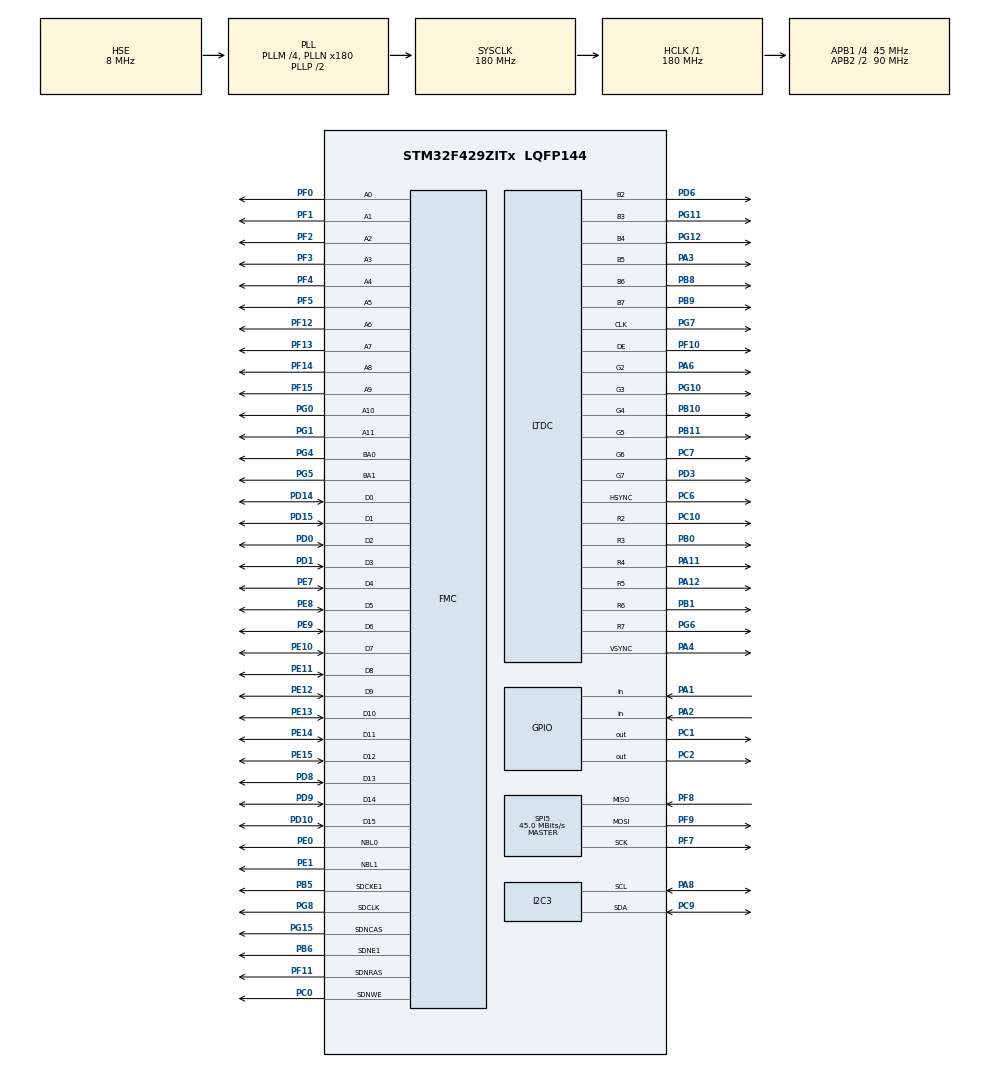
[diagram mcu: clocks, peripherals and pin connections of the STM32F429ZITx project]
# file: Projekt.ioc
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DMA2D.ColorMode=DMA2D_OUTPUT_RGB565
LTDC.ActiveH=320
LTDC.ActiveW=240
Mcu.Family=STM32F4
Mcu.Name=STM32F429ZITx
Mcu.Package=LQFP144
NVIC.PriorityGroup=NVIC_PRIORITYGROUP_4
NVIC.TIM6_DAC_IRQn=true\:0\:0\:false\:false\:true\:true\:true
PA1.Signal=GPIO_Input
PA11.Mode=RGB666
PA11.Signal=LTDC_R4
PA12.Mode=RGB666
PA12.Signal=LTDC_R5
PA2.Signal=GPIO_Input
PA3.Mode=RGB666
PA3.Signal=LTDC_B5
PA4.Mode=RGB666
PA4.Signal=LTDC_VSYNC
PA6.Mode=RGB666
PA6.Signal=LTDC_G2
PA8.Mode=I2C
PA8.Signal=I2C3_SCL
PB0.Mode=RGB666
PB0.Signal=LTDC_R3
PB1.Mode=RGB666
PB1.Signal=LTDC_R6
PB10.Mode=RGB666
PB10.Signal=LTDC_G4
PB11.Mode=RGB666
PB11.Signal=LTDC_G5
PB5.Mode=SdramChipSelect2_1
PB5.Signal=FMC_SDCKE1
PB6.Mode=SdramChipSelect2_1
PB6.Signal=FMC_SDNE1
PB8.Mode=RGB666
PB8.Signal=LTDC_B6
PB9.Mode=RGB666
PB9.Signal=LTDC_B7
PC0.Signal=FMC_SDNWE
PC1.Signal=GPIO_Output
PC10.Mode=RGB666
PC10.Signal=LTDC_R2
PC2.Signal=GPIO_Output
PC6.Mode=RGB666
PC6.Signal=LTDC_HSYNC
PC7.Mode=RGB666
PC7.Signal=LTDC_G6
PC9.Mode=I2C
PC9.Signal=I2C3_SDA
PD0.Signal=FMC_D2_DA2
PD1.Signal=FMC_D3_DA3
PD10.Signal=FMC_D15_DA15
PD14.Signal=FMC_D0_DA0
PD15.Signal=FMC_D1_DA1
PD3.Mode=RGB666
PD3.Signal=LTDC_G7
PD6.Mode=RGB666
PD6.Signal=LTDC_B2
PD8.Signal=FMC_D13_DA13
PD9.Signal=FMC_D14_DA14
PE0.Signal=FMC_NBL0
PE1.Signal=FMC_NBL1
PE10.Signal=FMC_D7_DA7
PE11.Signal=FMC_D8_DA8
PE12.Signal=FMC_D9_DA9
PE13.Signal=FMC_D10_DA10
PE14.Signal=FMC_D11_DA11
PE15.Signal=FMC_D12_DA12
PE7.Signal=FMC_D4_DA4
PE8.Signal=FMC_D5_DA5
PE9.Signal=FMC_D6_DA6
PF0.Signal=FMC_A0
PF1.Signal=FMC_A1
PF10.Mode=RGB666
PF10.Signal=LTDC_DE
PF11.Signal=FMC_SDNRAS
PF12.Signal=FMC_A6
PF13.Signal=FMC_A7
PF14.Signal=FMC_A8
PF15.Signal=FMC_A9
PF2.Signal=FMC_A2
PF3.Signal=FMC_A3
PF4.Signal=FMC_A4
PF5.Signal=FMC_A5
PF7.Mode=Full_Duplex_Master
PF7.Signal=SPI5_SCK
PF8.Mode=Full_Duplex_Master
PF8.Signal=SPI5_MISO
PF9.Mode=Full_Duplex_Master
PF9.Signal=SPI5_MOSI
PG0.Signal=FMC_A10
PG1.Signal=FMC_A11
PG10.Mode=RGB666
PG10.Signal=LTDC_G3
PG11.Mode=RGB666
PG11.Signal=LTDC_B3
PG12.Mode=RGB666
PG12.Signal=LTDC_B4
PG15.Signal=FMC_SDNCAS
PG4.Signal=FMC_A14_BA0
PG5.Signal=FMC_A15_BA1
PG6.Mode=RGB666
PG6.Signal=LTDC_R7
PG7.Mode=RGB666
PG7.Signal=LTDC_CLK
PG8.Signal=FMC_SDCLK
PH0/OSC_IN.Mode=HSE-External-Oscillator
PH0/OSC_IN.Signal=RCC_OSC_IN
PH1/OSC_OUT.Mode=HSE-External-Oscillator
PH1/OSC_OUT.Signal=RCC_OSC_OUT
ProjectManager.HeapSize=0x200
ProjectManager.StackSize=0x400
ProjectManager.TargetToolchain=STM32CubeIDE
RCC.48MHZClocksFreq_Value=90000000
RCC.AHBFreq_Value=180000000
RCC.APB1CLKDivider=RCC_HCLK_DIV4
RCC.APB1Freq_Value=45000000
RCC.APB1TimFreq_Value=90000000
RCC.APB2CLKDivider=RCC_HCLK_DIV2
RCC.APB2Freq_Value=90000000
RCC.APB2TimFreq_Value=180000000
RCC.CortexFreq_Value=180000000
RCC.HCLKFreq_Value=180000000
RCC.HSE_VALUE=8000000
RCC.HSI_VALUE=16000000
RCC.LSE_VALUE=32768
RCC.PLLM=4
RCC.PLLN=180
RCC.PLLSAIN=166
RCC.PLLSourceVirtual=RCC_PLLSOURCE_HSE
RCC.SYSCLKFreq_VALUE=180000000
RCC.SYSCLKSource=RCC_SYSCLKSOURCE_PLLCLK
RCC.VCOOutputFreq_Value=360000000
SH.FMC_A0.0=FMC_A0,12b-sda1
SH.FMC_A1.0=FMC_A1,12b-sda1
SH.FMC_A10.0=FMC_A10,12b-sda1
SH.FMC_A11.0=FMC_A11,12b-sda1
SH.FMC_A14_BA0.0=FMC_BA0,FourSdramBanks1
SH.FMC_A15_BA1.0=FMC_BA1,FourSdramBanks1
SH.FMC_A2.0=FMC_A2,12b-sda1
SH.FMC_A3.0=FMC_A3,12b-sda1
SH.FMC_A4.0=FMC_A4,12b-sda1
SH.FMC_A5.0=FMC_A5,12b-sda1
SH.FMC_A6.0=FMC_A6,12b-sda1
SH.FMC_A7.0=FMC_A7,12b-sda1
SH.FMC_A8.0=FMC_A8,12b-sda1
SH.FMC_A9.0=FMC_A9,12b-sda1
SH.FMC_D0_DA0.0=FMC_D0,sd-16b-d1
SH.FMC_D10_DA10.0=FMC_D10,sd-16b-d1
SH.FMC_D11_DA11.0=FMC_D11,sd-16b-d1
SH.FMC_D12_DA12.0=FMC_D12,sd-16b-d1
SH.FMC_D13_DA13.0=FMC_D13,sd-16b-d1
SH.FMC_D14_DA14.0=FMC_D14,sd-16b-d1
SH.FMC_D15_DA15.0=FMC_D15,sd-16b-d1
SH.FMC_D1_DA1.0=FMC_D1,sd-16b-d1
SH.FMC_D2_DA2.0=FMC_D2,sd-16b-d1
SH.FMC_D3_DA3.0=FMC_D3,sd-16b-d1
SH.FMC_D4_DA4.0=FMC_D4,sd-16b-d1
SH.FMC_D5_DA5.0=FMC_D5,sd-16b-d1
SH.FMC_D6_DA6.0=FMC_D6,sd-16b-d1
SH.FMC_D7_DA7.0=FMC_D7,sd-16b-d1
SH.FMC_D8_DA8.0=FMC_D8,sd-16b-d1
SH.FMC_D9_DA9.0=FMC_D9,sd-16b-d1
SH.FMC_NBL0.0=FMC_NBL0,Sd2ByteEnable1
SH.FMC_NBL1.0=FMC_NBL1,Sd2ByteEnable1
SH.FMC_SDCLK.0=FMC_SDCLK,12b-sda1
SH.FMC_SDNCAS.0=FMC_SDNCAS,12b-sda1
SH.FMC_SDNRAS.0=FMC_SDNRAS,12b-sda1
SH.FMC_SDNWE.0=FMC_SDNWE,12b-sda1
SPI5.CalculateBaudRate=45.0 MBits/s
SPI5.Direction=SPI_DIRECTION_2LINES
SPI5.Mode=SPI_MODE_MASTER
SPI5.VirtualType=VM_MASTER
TIM6.Period=9488
TIM6.Prescaler=9488
VP_DMA2D_VS_DMA2D.Mode=DMA2D_Activate
VP_TIM6_VS_ClockSourceINT.Mode=Enable_Timer
board=custom

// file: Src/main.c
/* USER CODE BEGIN Header */
/**
  ******************************************************************************
  * @file           : main.c
  * @brief          : Main program body
  ******************************************************************************
  * @attention
  *
  * <h2><center>&copy; Copyright (c) 2002 STMicroelectronics.
  * All rights reserved.</center></h2>
  *
  * This software component is licensed by ST under BSD 3-Clause license,
  * the "License"; You may not use this file except in compliance with the
  * License. You may obtain a copy of the License at:
  *                        opensource.org/licenses/BSD-3-Clause
  *
  ******************************************************************************
  */
/* USER CODE END Header */

#include "main.h"

/* USER CODE BEGIN Includes */
#include "stm32f429i_discovery_lcd.h"
#include "stm32f429xx.h"
#include "stdio.h"
#include <time.h>
/* USER CODE END Includes */

DMA2D_HandleTypeDef hdma2d;

I2C_HandleTypeDef hi2c3;

LTDC_HandleTypeDef hltdc;

SPI_HandleTypeDef hspi5;

TIM_HandleTypeDef htim6;

SDRAM_HandleTypeDef hsdram1;

/* USER CODE BEGIN PV */
int h = 0;
int min = 0;
int sec = 0;
/* USER CODE END PV */

void SystemClock_Config(void);
static void MX_GPIO_Init(void);
static void MX_DMA2D_Init(void);
static void MX_FMC_Init(void);
static void MX_I2C3_Init(void);
static void MX_LTDC_Init(void);
static void MX_SPI5_Init(void);
static void MX_TIM6_Init(void);

int main(void)
{

  /* MCU Configuration--------------------------------------------------------*/

  /* Reset of all peripherals, Initializes the Flash interface and the Systick. */
  HAL_Init();

  /* Configure the system clock */
  SystemClock_Config();

  /* Initialize all configured peripherals */
  MX_GPIO_Init();
  MX_DMA2D_Init();
  MX_FMC_Init();
  MX_I2C3_Init();
  MX_LTDC_Init();
  MX_SPI5_Init();
  MX_TIM6_Init();

  /* Infinite loop */
  /* USER CODE BEGIN WHILE */
   BSP_LCD_Init();
   BSP_LCD_LayerDefaultInit(LCD_BACKGROUND_LAYER, LCD_FRAME_BUFFER);
   BSP_LCD_Clear(LCD_COLOR_LIGHTBLUE);
//   BSP_LCD_SetBackColor(0x66a3ffaa);
   BSP_LCD_SetBackColor(LCD_COLOR_LIGHTBLUE);
   HAL_TIM_Base_Start_IT(&htim6);
   RCC->APB2ENR |= RCC_APB2ENR_ADC1EN; // włączenie zegara ADC1
   ADC1->CR2 |= ADC_CR2_ADON; // włączenie zasilania ADC1
   ADC->CCR |= ADC_CCR_TSVREFE; // włączenie czujnika temp
   ADC1->SQR3 |= 18U << ADC_SQR3_SQ1_Pos; // konfiguracja odczytu z 18 kanału (temperatura)

   int step = 0;
   int temp = 21;
   int temp_night = 18;
   float temp_house;
   int tryb = 1;
   while (1)
   {
	   HAL_Delay(500);
	   // Clear line
	   BSP_LCD_ClearStringLine(1);
	   BSP_LCD_ClearStringLine(2);
	   BSP_LCD_ClearStringLine(3);
	   BSP_LCD_ClearStringLine(4);
	   BSP_LCD_ClearStringLine(5);
	   // Deklaration
	   ADC1->CR2 |= ADC_CR2_SWSTART; // rozpoczęcie konwersji na ADC1
	   while((ADC1->SR & ADC_SR_EOC) == 0) { } // oczekiwanie na koniec konwersji
	   uint32_t value = ADC1->DR; // odczytanie wartości z ADC1

	   // Teperature house
	   	  float vval = (3.0f * value) / 4095.0f;
	   	  float temperature = (vval - 0.76) / (2.5/1000) + 25.0f;

		 temp_house = temperature-20;
		 char str_temp_house[100];
		 sprintf(str_temp_house, "T=%0.2fC", temp_house);
	   	 BSP_LCD_DisplayStringAtLine(1, (uint8_t*)&str_temp_house);

	   if(GPIO_PIN_SET == HAL_GPIO_ReadPin(GPIOA, GPIO_PIN_2)){
		   step++;
		   if(step == 5){
			   step=0;
		   }
	   }

	   // add time to click
	   if(GPIO_PIN_SET == HAL_GPIO_ReadPin(GPIOA, GPIO_PIN_1) && step==0){
		   if(h >= 24){
			   h=0;
		   }
		   h++;
	   } else if(GPIO_PIN_SET == HAL_GPIO_ReadPin(GPIOA, GPIO_PIN_1) && step==1){
		   if(min >= 60){
			   min=0;
		   }
		   min++;
	   }else if(GPIO_PIN_SET == HAL_GPIO_ReadPin(GPIOA, GPIO_PIN_1) && step==2){
		   if(sec >= 60){
		   	   sec=0;
		   }
		   sec++;
	   }
	   // add value to temperature
	   else if(GPIO_PIN_SET == HAL_GPIO_ReadPin(GPIOA, GPIO_PIN_1) && step==3){
		    if(temp >= 30){
		    	temp=18;
		   	}
		   	temp++;
		}
	   else if(GPIO_PIN_SET == HAL_GPIO_ReadPin(GPIOA, GPIO_PIN_1) && step==4){
	  		    if(temp_night >= 28){
	  		    	temp_night=16;
	  		   	}
	  		  temp_night++;
	  		}

	   // Display time
	  char time[100];
	  sprintf(time, "%02d:%02d:%02d", h,min,sec);
	  BSP_LCD_DisplayStringAtLine(2, (uint8_t*)&time);

	  // Day and night function
	  	  if (h >=22 || h<=7){
	  		  BSP_LCD_DisplayStringAtLine(3, (uint8_t*)"Tryb nocny");
	  		  tryb = 0;
	  	  }
	  	  else {
	  		 BSP_LCD_DisplayStringAtLine(3, (uint8_t*)"Tryb dzienny");
	  		 tryb = 1;
	  	  }

 	  // Launch defro
	  if( tryb == 1){
		  if (temp_house < temp){
			 HAL_GPIO_WritePin(GPIOC, GPIO_PIN_1, GPIO_PIN_RESET);
			 HAL_GPIO_WritePin(GPIOC, GPIO_PIN_2, GPIO_PIN_SET);
			 BSP_LCD_DisplayStringAtLine(0, (uint8_t*)"Zalaczony");
			  }
		  else {
			 HAL_GPIO_WritePin(GPIOC, GPIO_PIN_1, GPIO_PIN_SET);
			 HAL_GPIO_WritePin(GPIOC, GPIO_PIN_2, GPIO_PIN_RESET);
			 BSP_LCD_DisplayStringAtLine(0, (uint8_t*)"Wylaczony");
		  }
	  }
	  else{
		  if (temp_house < temp_night){
				 HAL_GPIO_WritePin(GPIOC, GPIO_PIN_1, GPIO_PIN_RESET);
				 HAL_GPIO_WritePin(GPIOC, GPIO_PIN_2, GPIO_PIN_SET);
				 BSP_LCD_DisplayStringAtLine(0, (uint8_t*)"Zalaczony");
				  }
			  else {
				 HAL_GPIO_WritePin(GPIOC, GPIO_PIN_1, GPIO_PIN_SET);
				 HAL_GPIO_WritePin(GPIOC, GPIO_PIN_2, GPIO_PIN_RESET);
				 BSP_LCD_DisplayStringAtLine(0, (uint8_t*)"Wylaczony");
			  }
	  }

 	 // Set temperature day
 	 char temper[100];
 	 sprintf(temper, "Dzien: %d", temp);
 	 BSP_LCD_DisplayStringAtLine(4, (uint8_t*) &temper);

 	 // Set temperature night

 	 char temper_night[100];
 	 sprintf(temper_night, "Noc: %d", temp_night);
	 BSP_LCD_DisplayStringAtLine(5, (uint8_t*) &temper_night);

 	  // Rectangle for step
 	 if(step == 0){
 		BSP_LCD_DrawRect(0, 42, 35, 30);
 	 }
 	 else if(step == 1){
 	 		BSP_LCD_DrawRect(50, 42, 35, 30);
 	 	 }
 	 else if(step == 2){
 	 		BSP_LCD_DrawRect(100, 42, 35, 30);
 	 	 }
 	 else if(step == 3){
 		    BSP_LCD_DrawRect(115, 89, 35, 30);
 	 }
 	 else if (step == 4){
 		 	BSP_LCD_DrawRect(83, 113, 35, 30);
 	 }

    /* USER CODE END WHILE */

   }
}

void SystemClock_Config(void)
{
  RCC_OscInitTypeDef RCC_OscInitStruct = {0};
  RCC_ClkInitTypeDef RCC_ClkInitStruct = {0};
  RCC_PeriphCLKInitTypeDef PeriphClkInitStruct = {0};

  /** Configure the main internal regulator output voltage
  */
  __HAL_RCC_PWR_CLK_ENABLE();
  __HAL_PWR_VOLTAGESCALING_CONFIG(PWR_REGULATOR_VOLTAGE_SCALE1);
  /** Initializes the CPU, AHB and APB busses clocks
  */
  RCC_OscInitStruct.OscillatorType = RCC_OSCILLATORTYPE_HSE;
  RCC_OscInitStruct.HSEState = RCC_HSE_ON;
  RCC_OscInitStruct.PLL.PLLState = RCC_PLL_ON;
  RCC_OscInitStruct.PLL.PLLSource = RCC_PLLSOURCE_HSE;
  RCC_OscInitStruct.PLL.PLLM = 4;
  RCC_OscInitStruct.PLL.PLLN = 180;
  RCC_OscInitStruct.PLL.PLLP = RCC_PLLP_DIV2;
  RCC_OscInitStruct.PLL.PLLQ = 4;
  if (HAL_RCC_OscConfig(&RCC_OscInitStruct) != HAL_OK)
  {
    Error_Handler();
  }
  /** Activate the Over-Drive mode
  */
  if (HAL_PWREx_EnableOverDrive() != HAL_OK)
  {
    Error_Handler();
  }
  /** Initializes the CPU, AHB and APB busses clocks
  */
  RCC_ClkInitStruct.ClockType = RCC_CLOCKTYPE_HCLK|RCC_CLOCKTYPE_SYSCLK
                              |RCC_CLOCKTYPE_PCLK1|RCC_CLOCKTYPE_PCLK2;
  RCC_ClkInitStruct.SYSCLKSource = RCC_SYSCLKSOURCE_PLLCLK;
  RCC_ClkInitStruct.AHBCLKDivider = RCC_SYSCLK_DIV1;
  RCC_ClkInitStruct.APB1CLKDivider = RCC_HCLK_DIV4;
  RCC_ClkInitStruct.APB2CLKDivider = RCC_HCLK_DIV2;

  if (HAL_RCC_ClockConfig(&RCC_ClkInitStruct, FLASH_LATENCY_5) != HAL_OK)
  {
    Error_Handler();
  }
  PeriphClkInitStruct.PeriphClockSelection = RCC_PERIPHCLK_LTDC;
  PeriphClkInitStruct.PLLSAI.PLLSAIN = 166;
  PeriphClkInitStruct.PLLSAI.PLLSAIR = 2;
  PeriphClkInitStruct.PLLSAIDivR = RCC_PLLSAIDIVR_2;
  if (HAL_RCCEx_PeriphCLKConfig(&PeriphClkInitStruct) != HAL_OK)
  {
    Error_Handler();
  }
}

static void MX_DMA2D_Init(void)
{

  hdma2d.Instance = DMA2D;
  hdma2d.Init.Mode = DMA2D_M2M;
  hdma2d.Init.ColorMode = DMA2D_OUTPUT_RGB565;
  hdma2d.Init.OutputOffset = 0;
  hdma2d.LayerCfg[1].InputOffset = 0;
  hdma2d.LayerCfg[1].InputColorMode = DMA2D_INPUT_RGB565;
  hdma2d.LayerCfg[1].AlphaMode = DMA2D_NO_MODIF_ALPHA;
  hdma2d.LayerCfg[1].InputAlpha = 0;
  if (HAL_DMA2D_Init(&hdma2d) != HAL_OK)
  {
    Error_Handler();
  }
  if (HAL_DMA2D_ConfigLayer(&hdma2d, 1) != HAL_OK)
  {
    Error_Handler();
  }

}

static void MX_I2C3_Init(void)
{

  hi2c3.Instance = I2C3;
  hi2c3.Init.ClockSpeed = 100000;
  hi2c3.Init.DutyCycle = I2C_DUTYCYCLE_2;
  hi2c3.Init.OwnAddress1 = 0;
  hi2c3.Init.AddressingMode = I2C_ADDRESSINGMODE_7BIT;
  hi2c3.Init.DualAddressMode = I2C_DUALADDRESS_DISABLE;
  hi2c3.Init.OwnAddress2 = 0;
  hi2c3.Init.GeneralCallMode = I2C_GENERALCALL_DISABLE;
  hi2c3.Init.NoStretchMode = I2C_NOSTRETCH_DISABLE;
  if (HAL_I2C_Init(&hi2c3) != HAL_OK)
  {
    Error_Handler();
  }
  /** Configure Analogue filter
  */
  if (HAL_I2CEx_ConfigAnalogFilter(&hi2c3, I2C_ANALOGFILTER_ENABLE) != HAL_OK)
  {
    Error_Handler();
  }
  /** Configure Digital filter
  */
  if (HAL_I2CEx_ConfigDigitalFilter(&hi2c3, 0) != HAL_OK)
  {
    Error_Handler();
  }

}

static void MX_LTDC_Init(void)
{

  LTDC_LayerCfgTypeDef pLayerCfg = {0};
  LTDC_LayerCfgTypeDef pLayerCfg1 = {0};

  hltdc.Instance = LTDC;
  hltdc.Init.HSPolarity = LTDC_HSPOLARITY_AL;
  hltdc.Init.VSPolarity = LTDC_VSPOLARITY_AL;
  hltdc.Init.DEPolarity = LTDC_DEPOLARITY_AL;
  hltdc.Init.PCPolarity = LTDC_PCPOLARITY_IPC;
  hltdc.Init.HorizontalSync = 7;
  hltdc.Init.VerticalSync = 3;
  hltdc.Init.AccumulatedHBP = 14;
  hltdc.Init.AccumulatedVBP = 5;
  hltdc.Init.AccumulatedActiveW = 254;
  hltdc.Init.AccumulatedActiveH = 325;
  hltdc.Init.TotalWidth = 260;
  hltdc.Init.TotalHeigh = 327;
  hltdc.Init.Backcolor.Blue = 0;
  hltdc.Init.Backcolor.Green = 0;
  hltdc.Init.Backcolor.Red = 0;
  if (HAL_LTDC_Init(&hltdc) != HAL_OK)
  {
    Error_Handler();
  }
  pLayerCfg.WindowX0 = 0;
  pLayerCfg.WindowX1 = 0;
  pLayerCfg.WindowY0 = 0;
  pLayerCfg.WindowY1 = 0;
  pLayerCfg.PixelFormat = LTDC_PIXEL_FORMAT_ARGB8888;
  pLayerCfg.Alpha = 0;
  pLayerCfg.Alpha0 = 0;
  pLayerCfg.BlendingFactor1 = LTDC_BLENDING_FACTOR1_CA;
  pLayerCfg.BlendingFactor2 = LTDC_BLENDING_FACTOR2_CA;
  pLayerCfg.FBStartAdress = 0;
  pLayerCfg.ImageWidth = 0;
  pLayerCfg.ImageHeight = 0;
  pLayerCfg.Backcolor.Blue = 0;
  pLayerCfg.Backcolor.Green = 0;
  pLayerCfg.Backcolor.Red = 0;
  if (HAL_LTDC_ConfigLayer(&hltdc, &pLayerCfg, 0) != HAL_OK)
  {
    Error_Handler();
  }
  pLayerCfg1.WindowX0 = 0;
  pLayerCfg1.WindowX1 = 0;
  pLayerCfg1.WindowY0 = 0;
  pLayerCfg1.WindowY1 = 0;
  pLayerCfg1.PixelFormat = LTDC_PIXEL_FORMAT_ARGB8888;
  pLayerCfg1.Alpha = 0;
  pLayerCfg1.Alpha0 = 0;
  pLayerCfg1.BlendingFactor1 = LTDC_BLENDING_FACTOR1_CA;
  pLayerCfg1.BlendingFactor2 = LTDC_BLENDING_FACTOR2_CA;
  pLayerCfg1.FBStartAdress = 0;
  pLayerCfg1.ImageWidth = 0;
  pLayerCfg1.ImageHeight = 0;
  pLayerCfg1.Backcolor.Blue = 0;
  pLayerCfg1.Backcolor.Green = 0;
  pLayerCfg1.Backcolor.Red = 0;
  if (HAL_LTDC_ConfigLayer(&hltdc, &pLayerCfg1, 1) != HAL_OK)
  {
    Error_Handler();
  }

}

static void MX_SPI5_Init(void)
{

  /* SPI5 parameter configuration*/
  hspi5.Instance = SPI5;
  hspi5.Init.Mode = SPI_MODE_MASTER;
  hspi5.Init.Direction = SPI_DIRECTION_2LINES;
  hspi5.Init.DataSize = SPI_DATASIZE_8BIT;
  hspi5.Init.CLKPolarity = SPI_POLARITY_LOW;
  hspi5.Init.CLKPhase = SPI_PHASE_1EDGE;
  hspi5.Init.NSS = SPI_NSS_SOFT;
  hspi5.Init.BaudRatePrescaler = SPI_BAUDRATEPRESCALER_2;
  hspi5.Init.FirstBit = SPI_FIRSTBIT_MSB;
  hspi5.Init.TIMode = SPI_TIMODE_DISABLE;
  hspi5.Init.CRCCalculation = SPI_CRCCALCULATION_DISABLE;
  hspi5.Init.CRCPolynomial = 10;
  if (HAL_SPI_Init(&hspi5) != HAL_OK)
  {
    Error_Handler();
  }

}

static void MX_TIM6_Init(void)
{

  TIM_MasterConfigTypeDef sMasterConfig = {0};

  htim6.Instance = TIM6;
  htim6.Init.Prescaler = 9488;
  htim6.Init.CounterMode = TIM_COUNTERMODE_UP;
  htim6.Init.Period = 9488;
  htim6.Init.AutoReloadPreload = TIM_AUTORELOAD_PRELOAD_DISABLE;
  if (HAL_TIM_Base_Init(&htim6) != HAL_OK)
  {
    Error_Handler();
  }
  sMasterConfig.MasterOutputTrigger = TIM_TRGO_RESET;
  sMasterConfig.MasterSlaveMode = TIM_MASTERSLAVEMODE_DISABLE;
  if (HAL_TIMEx_MasterConfigSynchronization(&htim6, &sMasterConfig) != HAL_OK)
  {
    Error_Handler();
  }

}

/* FMC initialization function */
static void MX_FMC_Init(void)
{

  FMC_SDRAM_TimingTypeDef SdramTiming = {0};

  /** Perform the SDRAM1 memory initialization sequence
  */
  hsdram1.Instance = FMC_SDRAM_DEVICE;
  /* hsdram1.Init */
  hsdram1.Init.SDBank = FMC_SDRAM_BANK2;
  hsdram1.Init.ColumnBitsNumber = FMC_SDRAM_COLUMN_BITS_NUM_8;
  hsdram1.Init.RowBitsNumber = FMC_SDRAM_ROW_BITS_NUM_12;
  hsdram1.Init.MemoryDataWidth = FMC_SDRAM_MEM_BUS_WIDTH_16;
  hsdram1.Init.InternalBankNumber = FMC_SDRAM_INTERN_BANKS_NUM_4;
  hsdram1.Init.CASLatency = FMC_SDRAM_CAS_LATENCY_1;
  hsdram1.Init.WriteProtection = FMC_SDRAM_WRITE_PROTECTION_DISABLE;
  hsdram1.Init.SDClockPeriod = FMC_SDRAM_CLOCK_DISABLE;
  hsdram1.Init.ReadBurst = FMC_SDRAM_RBURST_DISABLE;
  hsdram1.Init.ReadPipeDelay = FMC_SDRAM_RPIPE_DELAY_0;
  /* SdramTiming */
  SdramTiming.LoadToActiveDelay = 16;
  SdramTiming.ExitSelfRefreshDelay = 16;
  SdramTiming.SelfRefreshTime = 16;
  SdramTiming.RowCycleDelay = 16;
  SdramTiming.WriteRecoveryTime = 16;
  SdramTiming.RPDelay = 16;
  SdramTiming.RCDDelay = 16;

  if (HAL_SDRAM_Init(&hsdram1, &SdramTiming) != HAL_OK)
  {
    Error_Handler( );
  }

}

static void MX_GPIO_Init(void)
{
  GPIO_InitTypeDef GPIO_InitStruct = {0};

  /* GPIO Ports Clock Enable */
  __HAL_RCC_GPIOF_CLK_ENABLE();
  __HAL_RCC_GPIOH_CLK_ENABLE();
  __HAL_RCC_GPIOC_CLK_ENABLE();
  __HAL_RCC_GPIOA_CLK_ENABLE();
  __HAL_RCC_GPIOB_CLK_ENABLE();
  __HAL_RCC_GPIOG_CLK_ENABLE();
  __HAL_RCC_GPIOE_CLK_ENABLE();
  __HAL_RCC_GPIOD_CLK_ENABLE();

  /*Configure GPIO pin Output Level */
  HAL_GPIO_WritePin(GPIOC, GPIO_PIN_1|GPIO_PIN_2, GPIO_PIN_RESET);

  /*Configure GPIO pins : PC1 PC2 */
  GPIO_InitStruct.Pin = GPIO_PIN_1|GPIO_PIN_2;
  GPIO_InitStruct.Mode = GPIO_MODE_OUTPUT_PP;
  GPIO_InitStruct.Pull = GPIO_NOPULL;
  GPIO_InitStruct.Speed = GPIO_SPEED_FREQ_LOW;
  HAL_GPIO_Init(GPIOC, &GPIO_InitStruct);

  /*Configure GPIO pins : PA1 PA2 */
  GPIO_InitStruct.Pin = GPIO_PIN_1|GPIO_PIN_2;
  GPIO_InitStruct.Mode = GPIO_MODE_INPUT;
  GPIO_InitStruct.Pull = GPIO_NOPULL;
  HAL_GPIO_Init(GPIOA, &GPIO_InitStruct);

}

void Error_Handler(void)
{
}

/************************ (C) COPYRIGHT STMicroelectronics *****END OF FILE****/
